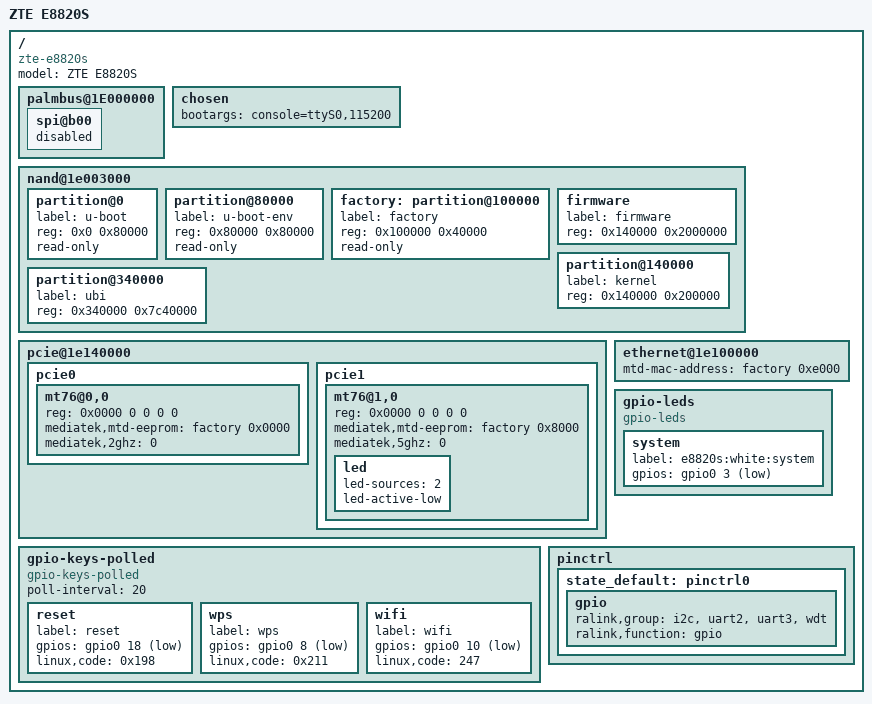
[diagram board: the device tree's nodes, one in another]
/dts-v1/;

/include/ "mt7621.dtsi"

/ {
	compatible = "zte-e8820s", "mediatek,mt7621-soc";
	model = "ZTE E8820S";

	palmbus@1E000000 {
		spi@b00 {
			status="disabled";
		};
	};

	chosen {
		bootargs = "console=ttyS0,115200";
	};

	nand@1e003000 {
		status = "okay";

		partition@0 {
			label = "u-boot";
			reg = <0x0 0x80000>;
			read-only;
		};

		partition@80000 {
			label = "u-boot-env";
			reg = <0x80000 0x80000>;
			read-only;
		};

		factory: partition@100000 {
			label = "factory";
			reg = <0x100000 0x40000>;
			read-only;
		};
		
		firmware {
			label = "firmware";
			reg = <0x140000 0x2000000>;
		};

		partition@140000 {
			label = "kernel";
			reg = <0x140000 0x200000>;
		};

		partition@340000 {
			label = "ubi";
			reg = <0x340000 0x7c40000>;
		};
	};

	pcie@1e140000 {
		status = "okay";

		pcie0 {
			mt76@0,0 {
				reg = <0x0000 0 0 0 0>;
				device_type = "pci";
				mediatek,mtd-eeprom = <&factory 0x0000>;
				mediatek,2ghz = <0>;
			};
		};

		pcie1 {
			mt76@1,0 {
				reg = <0x0000 0 0 0 0>;
				device_type = "pci";
				mediatek,mtd-eeprom = <&factory 0x8000>;
				mediatek,5ghz = <0>;

				led {
					led-sources = <2>;
					led-active-low;
				};
			};
		};
	};

	ethernet@1e100000 {
		mtd-mac-address = <&factory 0xe000>;
	};	

	gpio-leds {
		compatible = "gpio-leds";

		system {
			label = "e8820s:white:system";
			gpios = <&gpio0 3 1>;
		};
	};

	gpio-keys-polled {
		compatible = "gpio-keys-polled";
		#address-cells = <1>;
		#size-cells = <0>;
		poll-interval = <20>;

		reset {
			label = "reset";
			gpios = <&gpio0 18 1>;
			linux,code = <0x198>;
		};

		wps {
			label = "wps";
			gpios = <&gpio0 8 1>;
			linux,code = <0x211>;
		};

		wifi {
			label = "wifi";
			gpios = <&gpio0 10 1>;
			linux,code = <247>;
		};
	};

	pinctrl {
		state_default: pinctrl0 {
			gpio {
				ralink,group = "i2c", "uart2", "uart3", "wdt";
				ralink,function = "gpio";
			};
		};
	};

};
